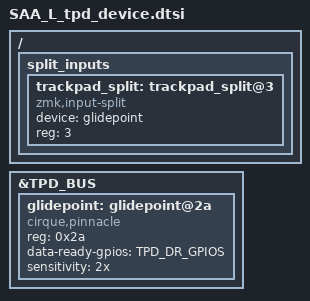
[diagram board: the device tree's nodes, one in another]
&TPD_BUS {
    glidepoint: glidepoint@2a {
        compatible = "cirque,pinnacle";
        reg = <0x2a>;
        status = "okay";
        data-ready-gpios = TPD_DR_GPIOS;
        sensitivity = "2x";
    };
};
/ {
    split_inputs {
        #address-cells = <1>;
        #size-cells = <0>;

        trackpad_split: trackpad_split@3 {
            compatible = "zmk,input-split";
            status = "okay";
            device = <&glidepoint>;
            reg = <3>;
        };
    };
};
